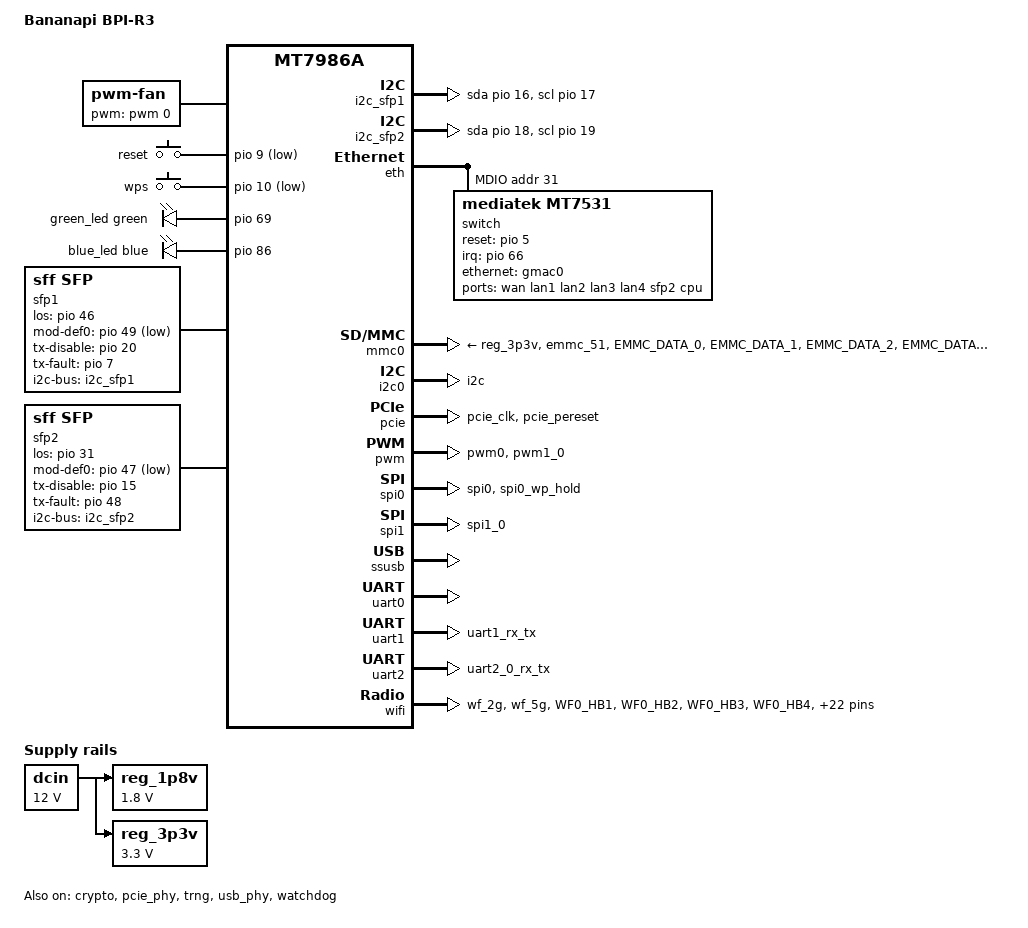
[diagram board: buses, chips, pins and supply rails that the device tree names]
// SPDX-License-Identifier: (GPL-2.0 OR MIT)
/*
 * Copyright (C) 2021 MediaTek Inc.
 * Authors: Sam.Shih <sam.shih@mediatek.com>
 *          Frank Wunderlich <frank-w@public-files.de>
 *          Daniel Golle <daniel@makrotopia.org>
 */

/dts-v1/;
#include <dt-bindings/gpio/gpio.h>
#include <dt-bindings/input/input.h>
#include <dt-bindings/leds/common.h>
#include <dt-bindings/pinctrl/mt65xx.h>

#include "mt7986a.dtsi"

/ {
	model = "Bananapi BPI-R3";
	chassis-type = "embedded";
	compatible = "bananapi,bpi-r3", "mediatek,mt7986a";

	aliases {
		serial0 = &uart0;
		ethernet0 = &gmac0;
		ethernet1 = &gmac1;
		led-boot = &green_led;
		led-failsafe = &green_led;
		led-running = &green_led;
		led-upgrade = &blue_led;
	};

	chosen {
		stdout-path = "serial0:115200n8";
	};

	dcin: regulator-12vd {
		compatible = "regulator-fixed";
		regulator-name = "12vd";
		regulator-min-microvolt = <12000000>;
		regulator-max-microvolt = <12000000>;
		regulator-boot-on;
		regulator-always-on;
	};

	fan: pwm-fan {
		compatible = "pwm-fan";
		#cooling-cells = <2>;
		/* cooling level (0, 1, 2) - pwm inverted */
		cooling-levels = <255 96 0>;
		pwms = <&pwm 0 10000>;
		status = "okay";
	};

	gpio-keys {
		compatible = "gpio-keys";

		reset-key {
			label = "reset";
			linux,code = <KEY_RESTART>;
			gpios = <&pio 9 GPIO_ACTIVE_LOW>;
		};

		wps-key {
			label = "wps";
			linux,code = <KEY_WPS_BUTTON>;
			gpios = <&pio 10 GPIO_ACTIVE_LOW>;
		};
	};

	/* i2c of the left SFP cage (wan) */
	i2c_sfp1: i2c-gpio-0 {
		compatible = "i2c-gpio";
		sda-gpios = <&pio 16 (GPIO_ACTIVE_HIGH | GPIO_OPEN_DRAIN)>;
		scl-gpios = <&pio 17 (GPIO_ACTIVE_HIGH | GPIO_OPEN_DRAIN)>;
		i2c-gpio,delay-us = <2>;
		#address-cells = <1>;
		#size-cells = <0>;
	};

	/* i2c of the right SFP cage (lan) */
	i2c_sfp2: i2c-gpio-1 {
		compatible = "i2c-gpio";
		sda-gpios = <&pio 18 (GPIO_ACTIVE_HIGH | GPIO_OPEN_DRAIN)>;
		scl-gpios = <&pio 19 (GPIO_ACTIVE_HIGH | GPIO_OPEN_DRAIN)>;
		i2c-gpio,delay-us = <2>;
		#address-cells = <1>;
		#size-cells = <0>;
	};

	leds {
		compatible = "gpio-leds";

		green_led: led-0 {
			color = <LED_COLOR_ID_GREEN>;
			function = LED_FUNCTION_POWER;
			gpios = <&pio 69 GPIO_ACTIVE_HIGH>;
			default-state = "on";
		};

		blue_led: led-1 {
			color = <LED_COLOR_ID_BLUE>;
			function = LED_FUNCTION_STATUS;
			gpios = <&pio 86 GPIO_ACTIVE_HIGH>;
			default-state = "off";
		};
	};

	reg_1p8v: regulator-1p8v {
		compatible = "regulator-fixed";
		regulator-name = "1.8vd";
		regulator-min-microvolt = <1800000>;
		regulator-max-microvolt = <1800000>;
		regulator-boot-on;
		regulator-always-on;
		vin-supply = <&dcin>;
	};

	reg_3p3v: regulator-3p3v {
		compatible = "regulator-fixed";
		regulator-name = "3.3vd";
		regulator-min-microvolt = <3300000>;
		regulator-max-microvolt = <3300000>;
		regulator-boot-on;
		regulator-always-on;
		vin-supply = <&dcin>;
	};

	/* left SFP cage (wan) */
	sfp1: sfp-1 {
		compatible = "sff,sfp";
		i2c-bus = <&i2c_sfp1>;
		los-gpios = <&pio 46 GPIO_ACTIVE_HIGH>;
		maximum-power-milliwatt = <3000>;
		mod-def0-gpios = <&pio 49 GPIO_ACTIVE_LOW>;
		tx-disable-gpios = <&pio 20 GPIO_ACTIVE_HIGH>;
		tx-fault-gpios = <&pio 7 GPIO_ACTIVE_HIGH>;
	};

	/* right SFP cage (lan) */
	sfp2: sfp-2 {
		compatible = "sff,sfp";
		i2c-bus = <&i2c_sfp2>;
		los-gpios = <&pio 31 GPIO_ACTIVE_HIGH>;
		mod-def0-gpios = <&pio 47 GPIO_ACTIVE_LOW>;
		maximum-power-milliwatt = <3000>;
		tx-disable-gpios = <&pio 15 GPIO_ACTIVE_HIGH>;
		tx-fault-gpios = <&pio 48 GPIO_ACTIVE_HIGH>;
	};
};

&cpu_thermal {
	cooling-maps {
		map-cpu-active-high {
			/* active: set fan to cooling level 2 */
			cooling-device = <&fan 2 2>;
			trip = <&cpu_trip_active_high>;
		};

		map-cpu-active-med {
			/* active: set fan to cooling level 1 */
			cooling-device = <&fan 1 1>;
			trip = <&cpu_trip_active_med>;
		};

		map-cpu-active-low {
			/* active: set fan to cooling level 0 */
			cooling-device = <&fan 0 0>;
			trip = <&cpu_trip_active_low>;
		};
	};
};

&crypto {
	status = "okay";
};

&eth {
	status = "okay";

	gmac0: mac@0 {
		compatible = "mediatek,eth-mac";
		reg = <0>;
		phy-mode = "2500base-x";

		fixed-link {
			speed = <2500>;
			full-duplex;
			pause;
		};
	};

	gmac1: mac@1 {
		compatible = "mediatek,eth-mac";
		reg = <1>;
		phy-mode = "2500base-x";
		sfp = <&sfp1>;
		managed = "in-band-status";
		openwrt,netdev-name = "sfp1";
	};

	mdio: mdio-bus {
		#address-cells = <1>;
		#size-cells = <0>;
	};
};

&mdio {
	switch: switch@31 {
		compatible = "mediatek,mt7531";
		reg = <31>;
		interrupt-controller;
		#interrupt-cells = <1>;
		interrupts-extended = <&pio 66 IRQ_TYPE_LEVEL_HIGH>;
		reset-gpios = <&pio 5 GPIO_ACTIVE_HIGH>;
	};
};

&mmc0 {
	pinctrl-names = "default", "state_uhs";
	pinctrl-0 = <&mmc0_pins_default>;
	pinctrl-1 = <&mmc0_pins_uhs>;
	vmmc-supply = <&reg_3p3v>;
	vqmmc-supply = <&reg_1p8v>;
};

&i2c0 {
	pinctrl-names = "default";
	pinctrl-0 = <&i2c_pins>;
	status = "okay";
};

&pcie {
	pinctrl-names = "default";
	pinctrl-0 = <&pcie_pins>;
	status = "okay";
};

&pcie_phy {
	status = "okay";
};

&pio {
	i2c_pins: i2c-pins {
		mux {
			function = "i2c";
			groups = "i2c";
		};
	};

	mmc0_pins_default: mmc0-pins {
		mux {
			function = "emmc";
			groups = "emmc_51";
		};
		conf-cmd-dat {
			pins = "EMMC_DATA_0", "EMMC_DATA_1", "EMMC_DATA_2",
			       "EMMC_DATA_3", "EMMC_DATA_4", "EMMC_DATA_5",
			       "EMMC_DATA_6", "EMMC_DATA_7", "EMMC_CMD";
			input-enable;
			drive-strength = <4>;
			bias-pull-up = <MTK_PUPD_SET_R1R0_01>; /* pull-up 10K */
		};
		conf-clk {
			pins = "EMMC_CK";
			drive-strength = <6>;
			bias-pull-down = <MTK_PUPD_SET_R1R0_10>; /* pull-down 50K */
		};
		conf-ds {
			pins = "EMMC_DSL";
			bias-pull-down = <MTK_PUPD_SET_R1R0_10>; /* pull-down 50K */
		};
		conf-rst {
			pins = "EMMC_RSTB";
			drive-strength = <4>;
			bias-pull-up = <MTK_PUPD_SET_R1R0_01>; /* pull-up 10K */
		};
	};

	mmc0_pins_uhs: mmc0-uhs-pins {
		mux {
			function = "emmc";
			groups = "emmc_51";
		};
		conf-cmd-dat {
			pins = "EMMC_DATA_0", "EMMC_DATA_1", "EMMC_DATA_2",
			       "EMMC_DATA_3", "EMMC_DATA_4", "EMMC_DATA_5",
			       "EMMC_DATA_6", "EMMC_DATA_7", "EMMC_CMD";
			input-enable;
			drive-strength = <4>;
			bias-pull-up = <MTK_PUPD_SET_R1R0_01>; /* pull-up 10K */
		};
		conf-clk {
			pins = "EMMC_CK";
			drive-strength = <6>;
			bias-pull-down = <MTK_PUPD_SET_R1R0_10>; /* pull-down 50K */
		};
		conf-ds {
			pins = "EMMC_DSL";
			bias-pull-down = <MTK_PUPD_SET_R1R0_10>; /* pull-down 50K */
		};
		conf-rst {
			pins = "EMMC_RSTB";
			drive-strength = <4>;
			bias-pull-up = <MTK_PUPD_SET_R1R0_01>; /* pull-up 10K */
		};
	};

	pcie_pins: pcie-pins {
		mux {
			function = "pcie";
			groups = "pcie_clk", "pcie_pereset";
		};
	};

	pwm_pins: pwm-pins {
		mux {
			function = "pwm";
			groups = "pwm0", "pwm1_0";
		};
	};

	spi_flash_pins: spi-flash-pins {
		mux {
			function = "spi";
			groups = "spi0", "spi0_wp_hold";
		};
	};

	spic_pins: spic-pins {
		mux {
			function = "spi";
			groups = "spi1_0";
		};
	};

	uart1_pins: uart1-pins {
		mux {
			function = "uart";
			groups = "uart1_rx_tx";
		};
	};

	uart2_pins: uart2-pins {
		mux {
			function = "uart";
			groups = "uart2_0_rx_tx";
		};
	};

	wf_2g_5g_pins: wf-2g-5g-pins {
		mux {
			function = "wifi";
			groups = "wf_2g", "wf_5g";
		};
		conf {
			pins = "WF0_HB1", "WF0_HB2", "WF0_HB3", "WF0_HB4",
			       "WF0_HB0", "WF0_HB0_B", "WF0_HB5", "WF0_HB6",
			       "WF0_HB7", "WF0_HB8", "WF0_HB9", "WF0_HB10",
			       "WF0_TOP_CLK", "WF0_TOP_DATA", "WF1_HB1",
			       "WF1_HB2", "WF1_HB3", "WF1_HB4", "WF1_HB0",
			       "WF1_HB5", "WF1_HB6", "WF1_HB7", "WF1_HB8",
			       "WF1_TOP_CLK", "WF1_TOP_DATA";
			drive-strength = <4>;
		};
	};

	wf_dbdc_pins: wf-dbdc-pins {
		mux {
			function = "wifi";
			groups = "wf_dbdc";
		};
		conf {
			pins = "WF0_HB1", "WF0_HB2", "WF0_HB3", "WF0_HB4",
			       "WF0_HB0", "WF0_HB0_B", "WF0_HB5", "WF0_HB6",
			       "WF0_HB7", "WF0_HB8", "WF0_HB9", "WF0_HB10",
			       "WF0_TOP_CLK", "WF0_TOP_DATA", "WF1_HB1",
			       "WF1_HB2", "WF1_HB3", "WF1_HB4", "WF1_HB0",
			       "WF1_HB5", "WF1_HB6", "WF1_HB7", "WF1_HB8",
			       "WF1_TOP_CLK", "WF1_TOP_DATA";
			drive-strength = <4>;
		};
	};

	wf_led_pins: wf-led-pins {
		mux {
			function = "led";
			groups = "wifi_led";
		};
	};
};

&pwm {
	pinctrl-names = "default";
	pinctrl-0 = <&pwm_pins>;
	status = "okay";
};

&spi0 {
	pinctrl-names = "default";
	pinctrl-0 = <&spi_flash_pins>;
	status = "okay";
};

&spi1 {
	pinctrl-names = "default";
	pinctrl-0 = <&spic_pins>;
	status = "okay";
};

&ssusb {
	status = "okay";
};

&switch {
	ports {
		#address-cells = <1>;
		#size-cells = <0>;

		port@0 {
			reg = <0>;
			label = "wan";
		};

		port@1 {
			reg = <1>;
			label = "lan1";
		};

		port@2 {
			reg = <2>;
			label = "lan2";
		};

		port@3 {
			reg = <3>;
			label = "lan3";
		};

		port@4 {
			reg = <4>;
			label = "lan4";
		};

		port5: port@5 {
			reg = <5>;
			label = "sfp2";
			phy-mode = "2500base-x";
			sfp = <&sfp2>;
			managed = "in-band-status";
		};

		port@6 {
			reg = <6>;
			label = "cpu";
			ethernet = <&gmac0>;
			phy-mode = "2500base-x";

			fixed-link {
				speed = <2500>;
				full-duplex;
				pause;
			};
		};
	};
};

&trng {
	status = "okay";
};

&uart0 {
	status = "okay";
};

&uart1 {
	pinctrl-names = "default";
	pinctrl-0 = <&uart1_pins>;
	status = "okay";
};

&uart2 {
	pinctrl-names = "default";
	pinctrl-0 = <&uart2_pins>;
	status = "okay";
};

&usb_phy {
	status = "okay";
};

&watchdog {
	status = "okay";
};

&wifi {
	status = "okay";
	pinctrl-names = "default";
	pinctrl-0 = <&wf_2g_5g_pins>, <&wf_led_pins>;

	mediatek,eeprom-data = <0x86790900 0x000c4326 0x60000000 0x00000000 0x00000000 0x00000000 0x00000000 0x00000000
				0x00000000 0x00000000 0x00000000 0x00000000 0x00000000 0x00000000 0x00000000 0x00000000
				0x00000000 0x00000000 0x00000000 0x00000000 0x00000000 0x00000000 0x00000000 0x01000000
				0x00000000 0x00000000 0x00000000 0x00000000 0x00000000 0x00000000 0x00000000 0x00000000
				0x00000000 0x00000000 0x00000000 0x00000000 0x00000000 0x00000000 0x00000000 0x00000000
				0x00000000 0x00000000 0x00000000 0x00000000 0x00000000 0x00000000 0x00000000 0x00000000
				0x00000000 0x00000000 0x00000000 0x00000000 0x00000000 0x00000000 0x00000000 0x00000000
				0x00000000 0x00000000 0x00000000 0x00000000 0x00000000 0x00000000 0x00000000 0x00000000
				0x00000000 0x00000800 0x00000000 0x00000000 0x00000000 0x00000000 0x00000000 0x00000000
				0x00000000 0x00000000 0x00000000 0x00000000 0x00000000 0x00000000 0x00000000 0x00000000
				0x00000000 0x00000000 0x00000000 0x00000000 0x00000000 0x00000000 0x00000000 0x00000000
				0x00000000 0x00000000 0x00000000 0x00000000 0x00000000 0x00000000 0x00000000 0x00000000
				0x00000000 0x00000000 0x00000000 0x00000000 0x24649090 0x00280000 0x05100000 0x00000000
				0x00000000 0x00000000 0x00000000 0x00000000 0x00000000 0x00000000 0x00000000 0x00000000
				0x00000000 0x00000000 0x00000000 0x00000000 0x00000000 0x00000000 0x00000000 0x00000000
				0x00000000 0x00000000 0x00000000 0x00000000 0x00000000 0x00000000 0x00000000 0x00000000
				0x00021e00 0x021e0002 0x1e00021e 0x00022800 0x02280002 0x28000228 0x00000000 0x00000000
				0x00000000 0x00000000 0x00000000 0x00000000 0x00000000 0x00000000 0x00008080 0x8080fdf7
				0x0903150d 0x80808080 0x80808080 0x05050d0d 0x1313c6c6 0xc3c3c200 0x00c200c2 0x00008182
				0x8585c2c2 0x82828282 0x858500c2 0xc2000081 0x82858587 0x87c2c200 0x81818285 0x858787c2
				0xc2000081 0x82858587 0x87c2c200 0x00818285 0x858787c2 0xc2000081 0x82858587 0x87c4c4c2
				0xc100c300 0xc3c3c100 0x818383c3 0xc3c3c100 0x81838300 0xc2c2c2c0 0x81828484 0x000000c3
				0xc3c3c100 0x81838386 0x86c3c3c3 0xc1008183 0x838686c2 0xc2c2c081 0x82848486 0x86c3c3c3
				0xc1008183 0x838686c3 0xc3c3c100 0x81838386 0x86c3c3c3 0xc1008183 0x83868622 0x28002228
				0x00222800 0x22280000 0xdddddddd 0xdddddddd 0xddbbbbbb 0xccccccdd 0xdddddddd 0xdddddddd
				0xeeeeeecc 0xccccdddd 0xdddddddd 0x004a5662 0x0000004a 0x56620000 0x004a5662 0x0000004a
				0x56620000 0x88888888 0x33333326 0x26262626 0x26262600 0x33333326 0x26262626 0x26262600
				0x33333326 0x26262626 0x26262600 0x33333326 0x26262626 0x26262600 0x00000000 0xf0f0cc00
				0x00000000 0x0000aaaa 0xaabbbbbb 0xcccccccc 0xccccbbbb 0xbbbbbbbb 0xbbbbbbaa 0xaaaabbbb
				0xbbaaaaaa 0x999999aa 0xaaaabbbb 0xbbcccccc 0x00000000 0x0000aaaa 0xaa000000 0xbbbbbbbb
				0xbbbbaaaa 0xaa999999 0xaaaaaaaa 0xaaaaaaaa 0xaaaaaaaa 0xaaaaaaaa 0xaaaabbbb 0xbbbbbbbb
				0x00000000 0x00000000 0x00000000 0x99999999 0x9999aaaa 0xaaaaaaaa 0x999999aa 0xaaaaaaaa
				0xaaaaaaaa 0xaaaaaaaa 0xaaaabbbb 0xbbbbbbbb 0x00000000 0x0000eeee 0xeeffffff 0xcccccccc
				0xccccdddd 0xddbbbbbb 0xccccccbb 0xbbbbbbbb 0xbbbbbbbb 0xbbbbbbbb 0xbbbbcccc 0xccdddddd
				0x00516200 0x686e0051 0x6200686e 0x00516200 0x686e0051 0x6200686e 0x00516200 0x686e0051
				0x6200686e 0x00516200 0x686e0051 0x6200686e 0x00516200 0x686e0051 0x6200686e 0x00516200
				0x686e0051 0x6200686e 0x00516200 0x686e0051 0x6200686e 0x00516200 0x686e0051 0x6200686e
				0x00516200 0x686e0051 0x6200686e 0x00516200 0x686e0051 0x6200686e 0x00516200 0x686e0051
				0x6200686e 0x00516200 0x686e0051 0x6200686e 0x00516200 0x686e0051 0x6200686e 0x00516200
				0x686e0051 0x6200686e 0x00516200 0x686e0051 0x6200686e 0x00516200 0x686e0051 0x6200686e
				0x88888888 0x88888888 0x88888888 0x88888888 0x88888888 0x88888888 0x88888888 0x88888888
				0x00000000 0x00000000 0x00000000 0x00000000 0x00000000 0x00000000 0x00000000 0x00000000
				0x00000000 0x00000000 0x00000000 0x00000000 0x00000000 0x00000000 0x00000000 0x00000000
				0x00000000 0x00000000 0x00000000 0x00000000 0x00000000 0x00000000 0x00000000 0x00000000
				0x00000000 0x00000000 0x00000000 0x00000000 0x00000000 0x00000000 0x00000000 0x00000000
				0x00000000 0x00000000 0x00000000 0x00000000 0x00000000 0x00000000 0x00000000 0x00000000
				0x00000000 0x00000000 0x00000000 0x00000000 0x00000000 0x00000000 0x00000000 0x00000000
				0x00000000 0x00000000 0x00000000 0x00000000 0x00000000 0x00000000 0x00000000 0x00000000
				0x00000000 0x00000000 0x00000000 0x00000000 0x00000000 0x00000000 0x00000000 0x00000000
				0x00000000 0x00000000 0x00000000 0x00000000 0x00000000 0x00000000 0x00000000 0x00000000
				0x00000000 0x00000000 0x00000000 0x00000000 0x00000001 0x06000100 0x01050002 0x00ff0300
				0xf900fe03 0x00000000 0x00000000 0x0000009b 0x6e370000 0x00000000 0x00fc0009 0x0a00fe00
				0x060700fe 0x00070800 0x05000b0a 0x00000000 0x00000000 0x000000e2 0x96460000 0x00000000
				0x000400f7 0xf8000300 0xfcfe0003 0x00fbfc00 0xee00e3f2 0x00000000 0x00000000 0x00000011
				0xbb550000 0x00000000 0x000600f6 0xfc000300 0xfbfe0004 0x00fafe00 0xf600ecf2 0x00000000
				0x00000000 0x0000001f 0xbf580000 0x00000000 0x000600f5 0xf6000400 0xf8f90004 0x00f7f800
				0xf700f0f4 0x00000000 0x00000000 0x00000024 0xbe570000 0x00000000 0x000800f8 0xfe000600
				0xf8fd0007 0x00f9fe00 0xf500f0f4 0x00000000 0x00000000 0x0000002d 0xd6610000 0x00000000
				0x000400f7 0xfc000500 0xf7fc0005 0x00f7fc00 0xf900f5f8 0x00000000 0x00000000 0x00000026
				0xd96e0000 0x00000000 0x000400f7 0xf9000600 0xf5f70005 0x00f5f800 0xf900f4f7 0x00000000
				0x00000000 0x0000001b 0xce690000 0x00000000 0x000300f8 0xf8000600 0xf6f60004 0x00f6f700
				0xf900f4f7 0x00000000 0x00000000 0x00000018 0xd8720000 0x00000000 0x00000000 0x02404002
				0x00000000 0x00000000 0x00000000 0x00000000 0x00000000 0x00000000 0x00000000 0x00000000
				0x00000000 0x00000000 0x00000000 0x00000000 0x00000000 0x00000000 0x00000000 0x00000000
				0x00000000 0x00000000 0x00000000 0x00000000 0x00000000 0x00000000 0x00000000 0x00000000
				0x00000000 0x00000000 0x00000000 0x00000000 0x00000000 0x00000000 0x00000000 0x00000000
				0x00000000 0x00000000 0x00000000 0x00000000 0x00000000 0x00000000 0x00000000 0x00000000
				0x00000000 0x00000000 0x00000000 0x00000000 0x00000000 0x00000000 0x00000000 0x00000000
				0x00000000 0x00000000 0x00000000 0x00000000 0x00000000 0x00000000 0x00000000 0x00000000
				0x00000000 0x00000000 0x00000000 0x00000000 0x00000000 0x00000000 0x00000000 0x00000000
				0x00000000 0x00000000 0x00000000 0x00000000 0x00000000 0x00000000 0x00000000 0x00000000
				0x00000000 0x00000000 0x00000000 0x00000000 0x00000000 0x00000000 0x00000000 0x00000000
				0xc1c2c1c2 0x41c341c3 0x3fc13fc1 0x40c13fc2 0x3fc240c1 0x41c040c0 0x3fc23fc2 0x40c13fc2
				0x3fc140c0 0x41c040c0 0x3fc33fc3 0x40c23fc2 0x3fc240c1 0x41c040c0 0x3fc23fc2 0x40c23fc2
				0x3fc140c1 0x41c040c0 0x00000000 0x00000000 0x41c741c7 0xc1c7c1c7 0x00000000 0x00000000
				0x3fc03fc0 0x3fc03fc0 0x3fc03fc0 0x3fc03fc0 0x3fc03fc0 0x3fc03fc0 0x3fc03fc0 0x3fc03fc0
				0x3fc03fc0 0x3fc03fc0 0x3fc03fc0 0x3fc03fc0 0x3fc03fc0 0x3fc03fc0 0x3fc03fc0 0x3fc03fc0
				0x00a0ce00 0x00000000 0xb6840000 0x00000000 0x00000000 0x00000000 0x18181818 0x18181818
				0x00000000 0x00000000 0x00000000 0x00000000 0x00000000 0x00000000 0x00000000 0x00000000
				0x00000000 0x00000000 0x00000000 0x00000000 0x00000000 0x00000000 0x00000000 0x00000000
				0x004b5763 0x0000004b 0x57630000 0x004b5763 0x0000004b 0x57630000 0x88888888 0x08474759
				0x69780849 0x49596d7a 0x0849495a 0x6d790848 0x48596c78 0x08484858 0x6a780848 0x48586a78
				0x08484858 0x6c78084a 0x4a5b6d79 0x08474759 0x697a0848 0x48596b79 0x08484859 0x6c7a0848
				0x48586c79 0x08484857 0x68770848 0x48576877 0x08484857 0x6a77084a 0x4a5a6a77 0x08464659
				0x69790848 0x48586b79 0x08484858 0x6c7a0848 0x48596c79 0x08484857 0x68770848 0x48576877
				0x08494958 0x6d7a084b 0x4b5c6c77 0x0847475a 0x6a7b0849 0x495a6e7c 0x0849495a 0x6e7c0849
				0x495b6e7c 0x08494959 0x6a7a0849 0x49596a7a 0x084a4a5a 0x6f7d084b 0x4b5c6e7b 0x00000000
				0x00000000 0x00000000 0x00000000 0x00000000 0x00000000 0x00000000 0x00000000 0x85848484
				0xc3c4c4c5 0xc4c3c33f 0xc3c3c2c2 0xc2c2c03f 0xc3c3c3c4 0xc4c4c33f 0xc2c2c2c2 0xc1c3c1c1
				0xc0c08282 0x83848686 0x88880000 0x00000000 0x00000000 0x00000000 0x00000000 0x00000000
				0x00000000 0x00000000 0x00000000 0x00000000 0x00000000 0x00000000 0x00000000 0x00000000
				0x00000000 0x00000000 0x00000000 0x00000000 0x00000000 0x00000000 0x00000000 0x00000000
				0x00000000 0x00000000 0x00000000 0x00000000 0x00000000 0x00000000 0x00000000 0x00000000
				0x00000000 0x00000000 0x00000000 0x00000000 0x00000000 0x00000000 0x00000000 0x00000000
				0x00000000 0x00000000 0x00000000 0x00000000 0x00000000 0x00000000 0x00000000 0x00000000
				0x00000000 0x00000000 0x00000000 0x00000000 0x00000000 0x00000000 0x00000000 0x00000000
				0x00000000 0x00000000 0x00000000 0x00000000 0x00000000 0x00000000 0x00000000 0x00000000
				0x00000000 0x00000000 0x00000000 0x00000000 0x00000000 0x00000000 0x00000000 0x00000000
				0x00000000 0x00000000 0x00000000 0x00000000 0x00000000 0x00000000 0x00000000 0x00000000
				0x00000000 0x00000000 0x00000000 0x00000000 0x00000000 0x00000000 0x00000000 0x00000000
				0x00000000 0x00000000 0x00000000 0x00000000 0x00000000 0x00000000 0x00000000 0x00000000
				0x00000000 0x00000000 0x00000000 0x00000000 0x00000000 0x00000000 0x00000000 0x00000000
				0x00000000 0x00000000 0x00000000 0x00000000 0x00000000 0x00000000 0x00000000 0x00000000
				0x00000000 0x00000000 0x00000000 0x00000000 0x00000000 0x00000000 0x00000000 0x00000000
				0x00000000 0x00000000 0x00000000 0x00000000 0x00000000 0x00000000 0x00000000 0x00000000
				0x00000000 0x00000000 0x00000000 0x00000000 0x00000000 0x00000000 0x00000000 0x00000000
				0x00000000 0x00000000 0x00000000 0x00000000 0x00000000 0x00000000 0x00000000 0x00000000
				0x00000000 0x00000000 0x00000000 0x00000000 0x00000000 0x00000000 0x00001111 0x00000000
				0x8080f703 0x10808080 0x80050d13 0x00000000 0x00000000 0x00000000 0x00000000 0x00000000
				0x00000000 0x00000000 0x00000000 0x00000000 0x00000000 0x00000000 0x00000000 0x00000000
				0x00000000 0x00000000 0x00000000 0x00000000 0x00000000 0x00000000 0x00000000 0x00000000
				0x00000000 0x00000000 0x00000000 0x00000000 0x00000000 0x00000000 0x00000000 0x00000000
				0x00000000 0x00000000 0x00000000 0x00000000 0x00000000 0x00000000 0x00000000 0x00000000
				0x00000000 0x00000000 0x00000000 0x000000a4 0xce000000 0x0000b684 0x00000000 0x00000000
				0x00000000 0x00000000 0x00000000 0x00000000 0x00000000 0x00000000 0x00000000 0x00000000
				0x00000000 0x00000000 0x00000000 0x00000000 0x00000000 0x00000000 0x00000000 0x00000000
				0x00000000 0x00000000 0x00000000 0x00000000 0x00000000 0x00000000 0x00000000 0x00000000
				0x00000000 0x00000000 0x00000000 0x00000000 0x00000000 0x00000000 0x00000000 0x00000000
				0x00000000 0x00000000 0x00000000 0x00000000 0x00000000 0x00000000 0x00000000 0x00000000
				0x00000000 0x00000000 0x00000000 0x00000000 0x00000000 0x00000000 0x00000000 0x00000000
				0x00000000 0x00000000 0x00000000 0x00000000 0x00000000 0x00000000 0x00000000 0x00000000
				0x00000000 0x00000000 0x00000000 0x00000000 0x00000000 0x00000000 0x00000000 0x00000000
				0x00000000 0x00000000 0x00000000 0x00000000 0x00000000 0x00000000 0x00000000 0x00000000
				0x00000000 0x00000000 0x00000000 0x00000000 0x00000000 0x00000000 0x00000000 0x00000000
				0x00000000 0x00000000 0x00000000 0x00000000 0x00000000 0x00000000 0x00000000 0x00000000
				0x00000000 0x00000000 0x00000000 0x00000000 0x00000000 0x00000000 0x00000000 0x00000000
				0x00000000 0x00000000 0x00000000 0x00000000 0x00000000 0x00000000 0x00000000 0x00000000
				0x00000000 0x00000000 0x00000000 0x00000000 0x00000000 0x00000000 0x00000000 0x00000000>;

	led {
		led-active-low;
	};
};

